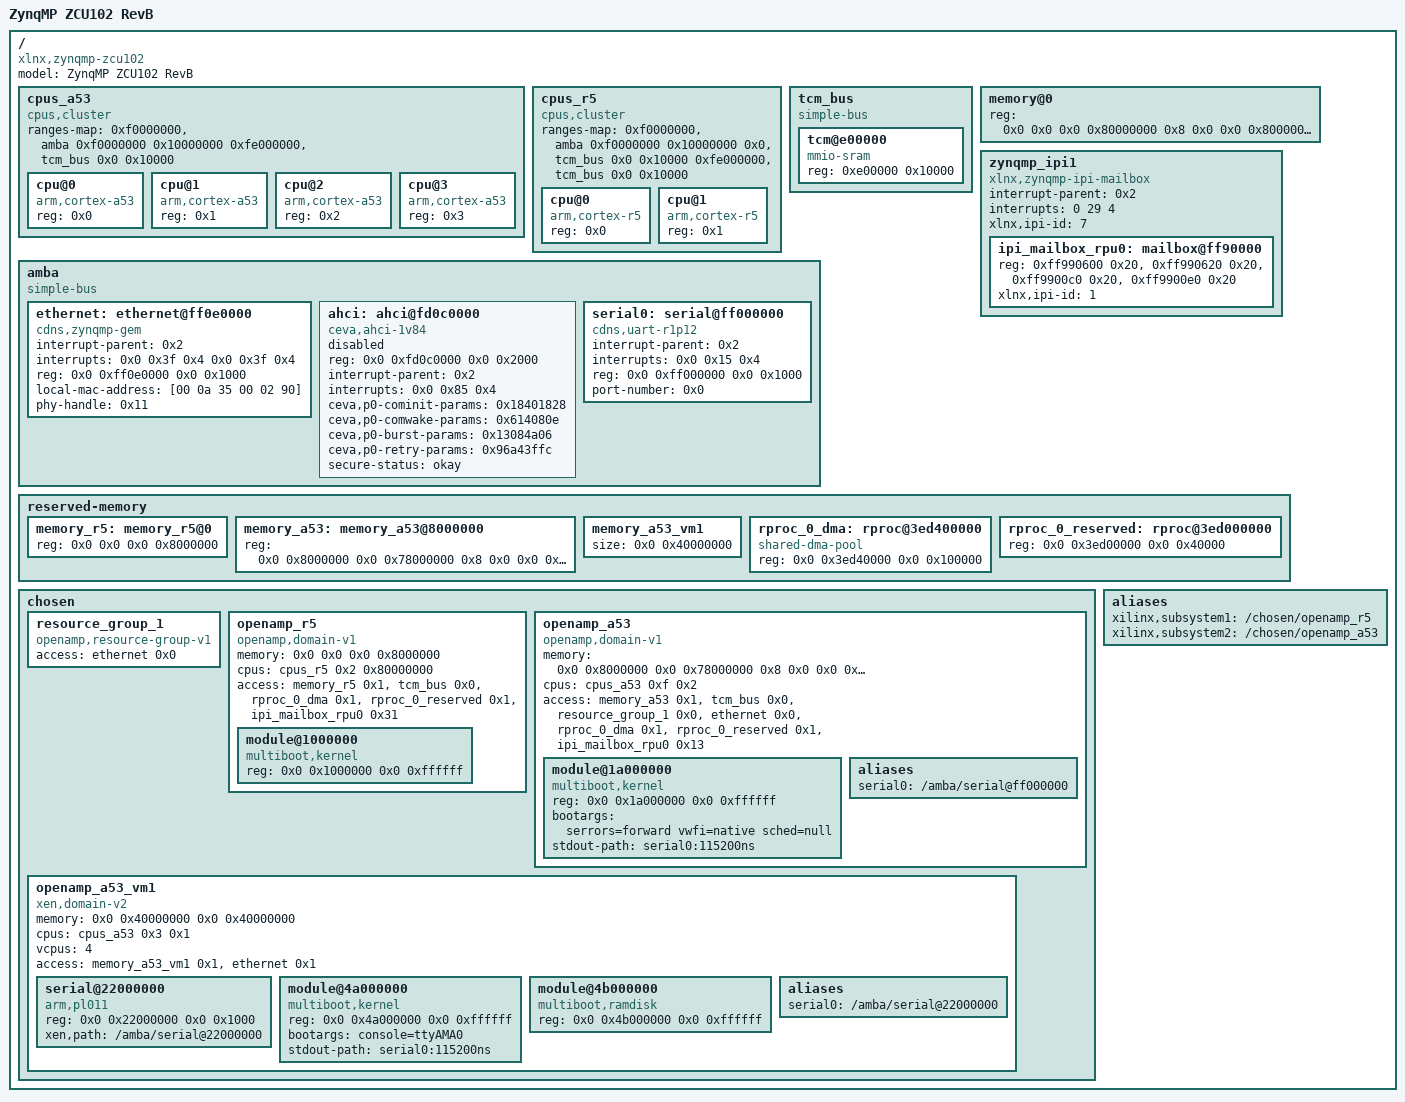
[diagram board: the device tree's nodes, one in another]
/dts-v1/;

/ {
	compatible = "xlnx,zynqmp-zcu102", "xlnx,zynqmp";
	#address-cells = <0x2>;
	#size-cells = <0x2>;
	model = "ZynqMP ZCU102 RevB";
	
	cpus_a53: cpus_a53 {
		#size-cells = <0x0>;
		#address-cells = <0x1>;
		compatible = "cpus,cluster";

		#ranges-size-cells = <0x1>;
		#ranges-address-cells = <0x1>;
		              /* amba bus */
		ranges-map = <0xf0000000 &amba 0xf0000000 0x10000000
		              /* tcm bus via amba bus */
		              0xfe000000 &tcm_bus 0x0 0x10000>;

		cpu@0 {
			reg = <0x0>;
			compatible = "arm,cortex-a53";
			device_type = "cpu";
		};
		cpu@1 {
			reg = <0x1>;
			compatible = "arm,cortex-a53";
			device_type = "cpu";
		};
		cpu@2 {
			reg = <0x2>;
			compatible = "arm,cortex-a53";
			device_type = "cpu";
		};
		cpu@3 {
			reg = <0x3>;
			compatible = "arm,cortex-a53";
			device_type = "cpu";
		};
	};

        cpus_r5: cpus_r5 {
		#size-cells = <0x0>;
		#address-cells = <0x1>;
		compatible = "cpus,cluster";

		#ranges-size-cells = <0x1>;
		#ranges-address-cells = <0x1>;
                      /* amba bus */
		ranges-map = <0xf0000000 &amba 0xf0000000 0x10000000
                      /* tcm bus */
				      0x0 &tcm_bus 0x0 0x10000
                      /* tcm bus via amba bus */
				      0xfe000000 &tcm_bus 0x0 0x10000>;

		cpu@0 {
			reg = <0x0>;
			compatible = "arm,cortex-r5";
			device_type = "cpu";
		};
		cpu@1 {
			reg = <0x1>;
			compatible = "arm,cortex-r5";
			device_type = "cpu";
		};
	};

	tcm_bus: tcm_bus {
		compatible = "simple-bus";
		#address-cells = <0x1>;
		#size-cells = <0x1>;

		tcm@e00000 {
			compatible = "mmio-sram";
			reg = <0xe00000 0x10000>;
		};
	};

	amba: amba {
		compatible = "simple-bus";
		#address-cells = <0x2>;
		#size-cells = <0x2>;

		ethernet: ethernet@ff0e0000 {
			compatible = "cdns,zynqmp-gem";
			interrupt-parent = <0x2>;
			interrupts = <0x0 0x3f 0x4 0x0 0x3f 0x4>;
			reg = <0x0 0xff0e0000 0x0 0x1000>;
			local-mac-address = [00 0a 35 00 02 90];
			phy-handle = <0x11>;
			linux,phandle = <0x22>;
			phandle = <0x22>;
			status = "okay";
		};

		ahci: ahci@fd0c0000 {
			compatible = "ceva,ahci-1v84";
			reg = <0x0 0xfd0c0000 0x0 0x2000>;
			interrupt-parent = <0x2>;
			interrupts = <0x0 0x85 0x4>;
			ceva,p0-cominit-params = <0x18401828>;
			ceva,p0-comwake-params = <0x614080e>;
			ceva,p0-burst-params = <0x13084a06>;
			ceva,p0-retry-params = <0x96a43ffc>;
			secure-status = "okay";
			status = "disabled";
		};

		serial0: serial@ff000000 {
			compatible = "cdns,uart-r1p12", "xlnx,xuartps";
			status = "okay";
			interrupt-parent = <0x2>;
			interrupts = <0x0 0x15 0x4>;
			reg = <0x0 0xff000000 0x0 0x1000>;
			device_type = "serial";
			port-number = <0x0>;
		};
	};

	memory@0 {
		device_type = "memory";
		reg = <0x0 0x0 0x0 0x80000000 0x8 0x0 0x0 0x80000000>;
	};

	zynqmp_ipi1 {
		compatible = "xlnx,zynqmp-ipi-mailbox";
		interrupt-parent = <0x2>;
		interrupts = <0 29 4>;
		xlnx,ipi-id = <7>;
		#address-cells = <1>;
		#size-cells = <1>;
		ranges;

		/* APU<->RPU0 IPI mailbox controller */
		ipi_mailbox_rpu0: mailbox@ff90000 {
			reg = <0xff990600 0x20>,
			      <0xff990620 0x20>,
			      <0xff9900c0 0x20>,
			      <0xff9900e0 0x20>;
			reg-names = "local_request_region",
				    "local_response_region",
				    "remote_request_region",
				    "remote_response_region";
			#mbox-cells = <1>;
			xlnx,ipi-id = <1>;
		};
	};

	reserved-memory {
		#address-cells = <0x2>;
		#size-cells = <0x2>;
		ranges;

		memory_r5: memory_r5@0 {
			reg = <0x0 0x0 0x0 0x8000000>;
		};

		memory_a53: memory_a53@8000000 {
			reg = <0x0 0x8000000 0x0 0x78000000 
			       0x8 0x0 0x0 0x80000000>;
		};

		memory_a53_vm1: memory_a53_vm1 {
			size = <0x0 0x40000000>;
		};

                rproc_0_dma: rproc@3ed400000 {
                        compatible = "shared-dma-pool";
			reg = <0x0 0x3ed40000 0x0 0x100000>;
		};

		rproc_0_reserved: rproc@3ed000000 {
			  reg = <0x0 0x3ed00000 0x0 0x40000>;
		};
	};

	chosen {
		#address-cells = <0x2>;
		#size-cells = <0x2>;

		resource_group_1: resource_group_1 {
			compatible = "openamp,resource-group-v1";

			access = <&ethernet 0x0>;
		};

		openamp_r5 {
			compatible = "openamp,domain-v1";
			#address-cells = <0x2>;
			#size-cells = <0x2>;
			/* 1:1 map, could be omitted */
			memory = <0x0 0x0 0x0 0x8000000>;
			/*
			 * Cluster | cpus-mask | execution-mode
			 *
			 * execution mode ARM-R CPUs:
			 * bit 30: lockstep (lockstep enabled == 1)
			 * bit 31: secure mode / normal mode (secure mode == 1)
			 */
			#cpus-mask-cells = <0x1>;
			cpus = <&cpus_r5 0x2 0x80000000>;
			/*
			 * Flags field, mapping specific
			 *
			 * memory and reserved-memory:
			 *   bit 0: 0/1: RO/RW
			 *
			 * xlnx,zynqmp-ipi-mailbox:
			 *   4 bits for each IPI channel to pass special flags
			 *   0-3   bits: channel 0
			 *   4-7   bits: channel 1
			 *   8-11  bits: channel 2
			 *   12-15 bits: channel 3
			 * each 4 bits:
			 *   bit 0: enable/disable (enable==1)
			 *   bit 1: TX/RX (TX==1)
			 *   bit 2-3: unused
			 *   
			 * Other cases: unused 
			 *
			 */
			access = <&memory_r5 0x1>, <&tcm_bus 0x0>,
			         <&rproc_0_dma 0x1>, <&rproc_0_reserved 0x1>, <&ipi_mailbox_rpu0 0x31>;

			module@1000000 {
				compatible = "multiboot,kernel", "multiboot,module";
				reg = <0x0 0x1000000 0x0 0xffffff>;
			};
		};

		openamp_a53 {
			compatible = "openamp,domain-v1";
			#address-cells = <0x2>;
			#size-cells = <0x2>;
			/* 1:1 map, could be omitted */
			memory = <0x0 0x8000000 0x0 0x78000000 
			          0x8 0x0 0x0 0x80000000>;
			/*
			 * Cluster | cpus-mask | execution-mode
			 *
			 * execution mode for ARM-A CPUs:
			 * 0x0: EL0
			 * 0x1: EL1
			 * 0x2: EL2
			 * 0x3: EL3
			 * bit 31: secure mode / normal mode (secure mode == 1)
			 */
			#cpus-mask-cells = <0x1>;
			cpus = <&cpus_a53 0xf 0x2>;

			access = <&memory_a53 0x1>, <&tcm_bus 0x0>, <&resource_group_1 0x0>, <&ethernet 0x0>,
			         <&rproc_0_dma 0x1>, <&rproc_0_reserved 0x1>, <&ipi_mailbox_rpu0 0x13>;

			module@1a000000 {
				compatible = "multiboot,kernel", "multiboot,module";
				reg = <0x0 0x1a000000 0x0 0xffffff>;
				bootargs = "serrors=forward vwfi=native sched=null";
				stdout-path = "serial0:115200ns";
			};

			aliases {
				serial0 = "/amba/serial@ff000000";
			};
		};

		openamp_a53_vm1 {
			compatible = "xen,domain-v2", "openamp,domain-v1";
			#address-cells = <0x2>;
			#size-cells = <0x2>;
			/* Xen default VM address map, must be specified */
			memory = <0x0 0x40000000 0x0 0x40000000>;
			/*
			 * Cluster | cpus-mask | execution-mode
			 *
			 * execution mode ARM-A CPUs:
			 * 0x0: EL0
			 * 0x1: EL1
			 * 0x2: EL2
			 * 0x3: EL3
			 * bit 31: secure mode / normal mode (secure mode == 1)
			 */
			#cpus-mask-cells = <0x1>;
			cpus = <&cpus_a53 0x3 0x1>;
			/* how many vcpus */
			vcpus = <4>;
			access = <&memory_a53_vm1 0x1>, <&ethernet 0x1>;

			/* 
			 * Generated vgic, add it here, or not?
			 * Emulated and assigned devices might have to reference to
			 * it.
			 */
			/* Generated arch-timer, add it here, or not? */

			/* UART emulated device */
		        serial@22000000 {
		                compatible = "arm,pl011", "arm,primecell";
		                reg = <0x0 0x22000000 0x0 0x1000>;
				/*
				 * Where the node is located in the output domain device
				 * tree
				 */
				xen,path = "/amba/serial@22000000";
		        };

			module@4a000000 {
				compatible = "multiboot,kernel", "multiboot,module";
				reg = <0x0 0x4a000000 0x0 0xffffff>;
				bootargs = "console=ttyAMA0";
				stdout-path = "serial0:115200ns";
			};

			module@4b000000 {
				compatible = "multiboot,ramdisk", "multiboot,module";
				reg = <0x0 0x4b000000 0x0 0xffffff>;
			};

			aliases {
				serial0 = "/amba/serial@22000000";
			};
		};
	};

	aliases {
		xilinx,subsystem1 = "/chosen/openamp_r5";
		xilinx,subsystem2 = "/chosen/openamp_a53";
	};
};
